# CC1314R10 register map
File version: 1.0
CPU: CM33 1.0, other endian, MPU, FPU, 3 interrupt priority bits
Registers are 32-bit, read-write, reset 0x0 unless marked. A register's access mark holds for its fields unless they carry their own. Offsets are from the block's base; [hi:lo] are bit positions; {n}, {i} and the like mark numbered series.

## CPU_FPB — Cortex-M's Flash Patch and Breakpoint (FPB)
Base 0xE0002000
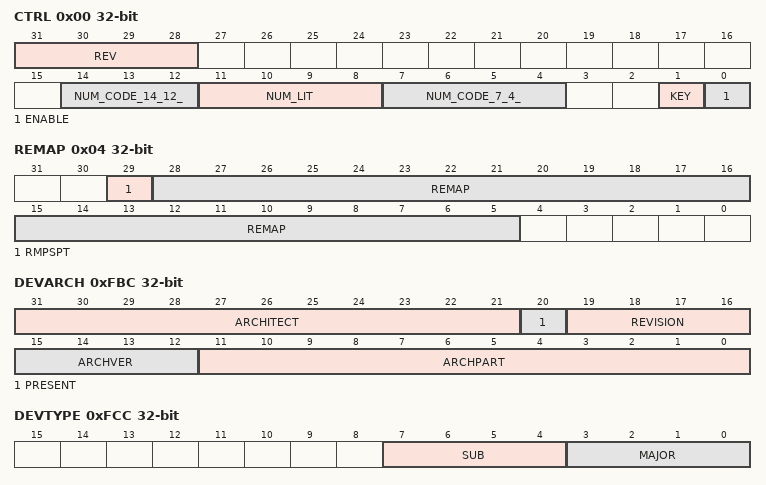
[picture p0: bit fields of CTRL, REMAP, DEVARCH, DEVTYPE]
0x00 CTRL — Provides FPB implementation information, and the global enable for the FPB unit
  [31:28] REV ro — [31:28] Flash Patch and Breakpoint Unit architecture revision
  [14:12] NUM_CODE_14_12_ ro — [14:12] Indicates the number of implemented instruction address comparators. Zero indicates no Instruction Address comparators are implemented. The Instruction Address comparators are numbered from 0 to NUM_CODE - 1
  [11:8] NUM_LIT ro — [11:8] Indicates the number of implemented literal address comparators. The Literal Address comparators are numbered from NUM_CODE to NUM_CODE + NUM_LIT - 1
  [7:4] NUM_CODE_7_4_ ro — [7:4] Indicates the number of implemented instruction address comparators. Zero indicates no Instruction Address comparators are implemented. The Instruction Address comparators are numbered from 0 to NUM_CODE - 1
  [1] KEY — [1:1] Writes to the FP_CTRL are ignored unless KEY is concurrently written to one
  [0] ENABLE — [0:0] Enables the FPB
0x04 REMAP — Indicates whether the implementation supports Flash Patch remap and, if it does, holds the target address for remap
  [29] RMPSPT ro — [29:29] Indicates whether the FPB unit supports the Flash Patch remap function
  [28:5] REMAP ro — [28:5] Holds the bits[28:5] of the Flash Patch remap address
{0x8+4i} COMP{i} (i=0..7) — Holds an address for comparison. The effect of the match depends on the configuration of the FPB and whether the comparator is an instruction address comparator or a literal address comparator
  [0] BE — [0:0] Selects between flashpatch and breakpoint functionality
0xFBC DEVARCH — Provides CoreSight discovery information for the FPB
  [31:21] ARCHITECT ro — [31:21] Defines the architect of the component. Bits [31:28] are the JEP106 continuation code (JEP106 bank ID, minus 1) and bits [27:21] are the JEP106 ID code.
  [20] PRESENT ro — [20:20] Defines that the DEVARCH register is present
  [19:16] REVISION ro — [19:16] Defines the architecture revision of the component
  [15:12] ARCHVER ro — [15:12] Defines the architecture version of the component
  [11:0] ARCHPART ro — [11:0] Defines the architecture of the component
0xFCC DEVTYPE — Provides CoreSight discovery information for the FPB
  [7:4] SUB ro — [7:4] Component sub-type
  [3:0] MAJOR ro — [3:0] Component major type
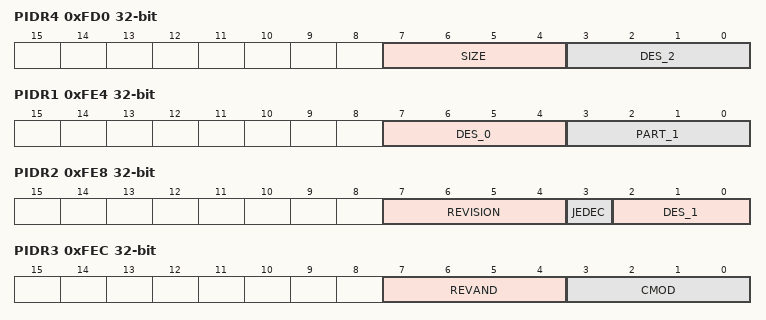
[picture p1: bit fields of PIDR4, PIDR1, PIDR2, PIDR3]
0xFD0 PIDR4 — Provides CoreSight discovery information for the FP
  [7:4] SIZE ro — [7:4] See CoreSight Architecture Specification
  [3:0] DES_2 ro — [3:0] See CoreSight Architecture Specification
{0xFC0+4i} PIDR{i} (i=5..7) — Provides CoreSight discovery information for the FP
0xFE0 PIDR0 — Provides CoreSight discovery information for the FP
  [7:0] PART_0 ro — [7:0] See CoreSight Architecture Specification
0xFE4 PIDR1 — Provides CoreSight discovery information for the FP
  [7:4] DES_0 ro — [7:4] See CoreSight Architecture Specification
  [3:0] PART_1 ro — [3:0] See CoreSight Architecture Specification
0xFE8 PIDR2 — Provides CoreSight discovery information for the FP
  [7:4] REVISION ro — [7:4] See CoreSight Architecture Specification
  [3] JEDEC ro — [3:3] See CoreSight Architecture Specification
  [2:0] DES_1 ro — [2:0] See CoreSight Architecture Specification
0xFEC PIDR3 — Provides CoreSight discovery information for the FP
  [7:4] REVAND ro — [7:4] See CoreSight Architecture Specification
  [3:0] CMOD ro — [3:0] See CoreSight Architecture Specification
0xFF0 CIDR0 — Provides CoreSight discovery information for the FP
  [7:0] PRMBL_0 ro — [7:0] See CoreSight Architecture Specification
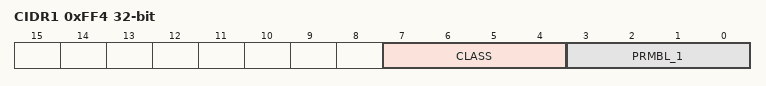
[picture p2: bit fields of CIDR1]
0xFF4 CIDR1 — Provides CoreSight discovery information for the FP
  [7:4] CLASS ro — [7:4] See CoreSight Architecture Specification
  [3:0] PRMBL_1 ro — [3:0] See CoreSight Architecture Specification
0xFF8 CIDR2 — Provides CoreSight discovery information for the FP
  [7:0] PRMBL_2 ro — [7:0] See CoreSight Architecture Specification
0xFFC CIDR3 — Provides CoreSight discovery information for the FP
  [7:0] PRMBL_3 ro — [7:0] See CoreSight Architecture Specification
